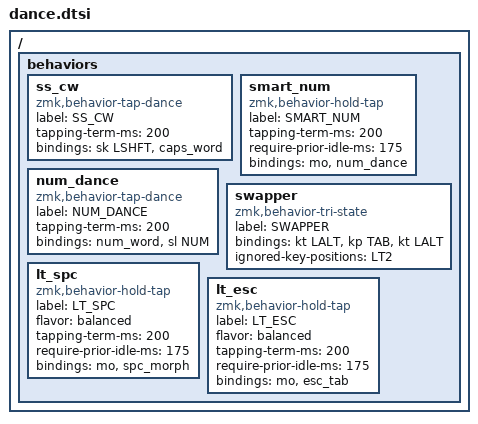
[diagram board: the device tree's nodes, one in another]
/ {
  behaviors {
    ss_cw: ss_cw {
      compatible = "zmk,behavior-tap-dance";
      label = "SS_CW";
      #binding-cells = <0>;
      tapping-term-ms = <200>;
      bindings = <&sk LSHFT>, <&caps_word>;
    };
    smart_num: smart_num {
      compatible = "zmk,behavior-hold-tap";
      label = "SMART_NUM";
      #binding-cells = <2>;
      tapping-term-ms = <200>;
      require-prior-idle-ms = <175>;
      bindings = <&mo>, <&num_dance>;
     };
    num_dance: num_dance {
      compatible = "zmk,behavior-tap-dance";
      label = "NUM_DANCE";
      #binding-cells = <0>;
      tapping-term-ms = <200>;
      bindings = <&num_word>, <&sl NUM>;
     };
    swapper: swapper {
      compatible = "zmk,behavior-tri-state";
      label = "SWAPPER";
      #binding-cells = <0>;
      bindings = <&kt LALT>, <&kp TAB>, <&kt LALT>;
      ignored-key-positions = <LT2>;
     };
    lt_spc: lt_spc {
      compatible = "zmk,behavior-hold-tap";
      label = "LT_SPC";
      #binding-cells = <2>;
      flavor = "balanced";
      tapping-term-ms = <200>;
      require-prior-idle-ms = <175>;
      bindings = <&mo>, <&spc_morph>;
     };
    lt_esc: lt_esc {
      compatible = "zmk,behavior-hold-tap";
      label = "LT_ESC";
      #binding-cells = <2>;
      flavor = "balanced";
      tapping-term-ms = <200>;
      require-prior-idle-ms = <175>;
      bindings = <&mo>, <&esc_tab>;
     };;
  };
};
